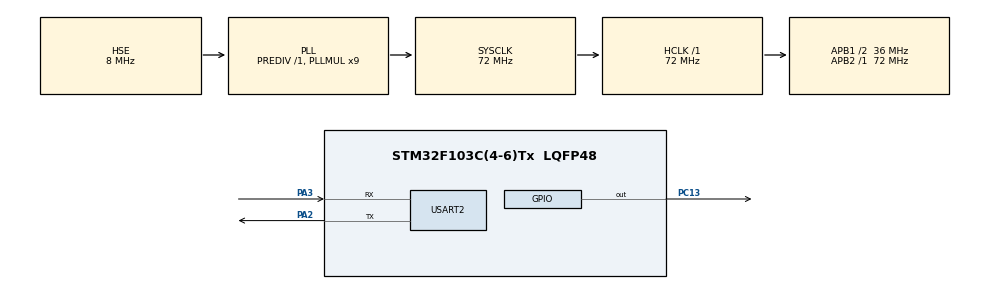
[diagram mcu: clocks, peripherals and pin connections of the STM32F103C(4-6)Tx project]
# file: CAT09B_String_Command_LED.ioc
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Mcu.Family=STM32F1
Mcu.Name=STM32F103C(4-6)Tx
Mcu.Package=LQFP48
NVIC.PriorityGroup=NVIC_PRIORITYGROUP_4
PA13.Mode=Serial_Wire
PA13.Signal=SYS_JTMS-SWDIO
PA14.Mode=Serial_Wire
PA14.Signal=SYS_JTCK-SWCLK
PA2.Mode=Asynchronous
PA2.Signal=USART2_TX
PA3.Mode=Asynchronous
PA3.Signal=USART2_RX
PC13-TAMPER-RTC.Signal=GPIO_Output
PD0-OSC_IN.Mode=HSE-External-Oscillator
PD0-OSC_IN.Signal=RCC_OSC_IN
PD1-OSC_OUT.Mode=HSE-External-Oscillator
PD1-OSC_OUT.Signal=RCC_OSC_OUT
ProjectManager.HeapSize=0x200
ProjectManager.StackSize=0x400
ProjectManager.TargetToolchain=STM32CubeIDE
RCC.AHBFreq_Value=72000000
RCC.APB1CLKDivider=RCC_HCLK_DIV2
RCC.APB1Freq_Value=36000000
RCC.APB1TimFreq_Value=72000000
RCC.APB2Freq_Value=72000000
RCC.APB2TimFreq_Value=72000000
RCC.HCLKFreq_Value=72000000
RCC.PLLMUL=RCC_PLL_MUL9
RCC.PLLSourceVirtual=RCC_PLLSOURCE_HSE
RCC.SYSCLKFreq_VALUE=72000000
RCC.SYSCLKSource=RCC_SYSCLKSOURCE_PLLCLK
RCC.USBFreq_Value=72000000
USART2.VirtualMode=VM_ASYNC
board=custom

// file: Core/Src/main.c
/* USER CODE BEGIN Header */
/**
  ******************************************************************************
  * @file           : main.c
  * @brief          : CAT 9 - Task 9B : String-based application logic over UART
  *                    Commands LED ON / LED OFF / LED TOGGLE (+ STATUS, CRLF TEST, HELP) control PC13.
  ******************************************************************************
  * @attention
  *
  * Copyright (c) 2026 STMicroelectronics.
  * All rights reserved.
  *
  * This software is licensed under terms that can be found in the LICENSE file
  * in the root directory of this software component.
  * If no LICENSE file comes with this software, it is provided AS-IS.
  *
  ******************************************************************************
  */
/* USER CODE END Header */
#include "main.h"

/* USER CODE BEGIN Includes */
#include <string.h>
#include <ctype.h>
/* USER CODE END Includes */

/* USER CODE BEGIN PD */
#define PC_UART          (&huart2)       /* USART2 PA2/PA3, 115200-8-N-1 */
#define CMD_MAX_LEN      32U

#define LED_PORT         GPIOC           /* PC13, active-low */
#define LED_PIN          GPIO_PIN_13
#define LED_ON_LEVEL     GPIO_PIN_RESET
#define LED_OFF_LEVEL    GPIO_PIN_SET
/* USER CODE END PD */

UART_HandleTypeDef huart2;

/* USER CODE BEGIN PV */
static char    cmd_buf[CMD_MAX_LEN + 1];
static uint8_t cmd_len = 0;
static uint8_t cmd_too_long = 0;   /* set when more than CMD_MAX_LEN characters arrive */
static uint8_t led_on  = 0;
/* USER CODE END PV */

void SystemClock_Config(void);
static void MX_GPIO_Init(void);
static void MX_USART2_UART_Init(void);

/* USER CODE BEGIN 0 */
static void uart_puts(const char *s)
{
  HAL_UART_Transmit(PC_UART, (uint8_t *)s, (uint16_t)strlen(s), HAL_MAX_DELAY);
}

static void uart_putc(char c)
{
  HAL_UART_Transmit(PC_UART, (uint8_t *)&c, 1, HAL_MAX_DELAY);
}

static void led_apply(void)
{
  HAL_GPIO_WritePin(LED_PORT, LED_PIN, led_on ? LED_ON_LEVEL : LED_OFF_LEVEL);
}

/* Upper-case the command and remove leading/trailing spaces, so
 * "led on", "LED ON " and " Led On" are all accepted. */
static char *normalise(char *s)
{
  char *end;
  while (*s == ' ') s++;
  for (char *p = s; *p; p++) *p = (char)toupper((unsigned char)*p);
  end = s + strlen(s);
  while (end > s && end[-1] == ' ') *--end = '\0';
  return s;
}

/* Demonstrates the effect of CR and LF on the terminal (lab sheet table) */
static void crlf_demo(void)
{
  uart_puts("HELLO\r\n");               /* new line, start of line         */
  uart_puts("HELLO\r");                 /* back to start: next text overwrites */
  uart_puts("HELLO\n");                 /* down one line, same column       */
  uart_puts("\r\nHELLO\r\nWORLD\r\n");  /* two separate lines               */
}

static void handle_command(char *raw)
{
  char *cmd = normalise(raw);

  if (strcmp(cmd, "LED ON") == 0)          { led_on = 1;       led_apply(); uart_puts("OK: LED is ON\r\n"); }
  else if (strcmp(cmd, "LED OFF") == 0)    { led_on = 0;       led_apply(); uart_puts("OK: LED is OFF\r\n"); }
  else if (strcmp(cmd, "LED TOGGLE") == 0) { led_on = !led_on; led_apply(); uart_puts(led_on ? "OK: LED toggled -> ON\r\n" : "OK: LED toggled -> OFF\r\n"); }
  else if (strcmp(cmd, "STATUS") == 0)     { uart_puts(led_on ? "LED is ON\r\n" : "LED is OFF\r\n"); }
  else if (strcmp(cmd, "CRLF TEST") == 0)  { crlf_demo(); }
  else if (strcmp(cmd, "HELP") == 0)       { uart_puts("Commands: LED ON | LED OFF | LED TOGGLE | STATUS | CRLF TEST | HELP\r\n"); }
  else                                     { uart_puts("ERR: unknown command '"); uart_puts(cmd); uart_puts("' (type HELP)\r\n"); }
}
/* USER CODE END 0 */

int main(void)
{

  /* MCU Configuration--------------------------------------------------------*/

  /* Reset of all peripherals, Initializes the Flash interface and the Systick. */
  HAL_Init();

  /* Configure the system clock */
  SystemClock_Config();

  /* Initialize all configured peripherals */
  MX_GPIO_Init();
  MX_USART2_UART_Init();
  /* USER CODE BEGIN 2 */
  led_on = 0;
  led_apply();
  uart_puts("\r\nCAT9B - UART command interface. Type HELP and press Enter.\r\n> ");
  /* USER CODE END 2 */

  /* Infinite loop */
  while (1)
  {

    /* USER CODE BEGIN 3 */
    uint8_t ch;

    if (HAL_UART_Receive(PC_UART, &ch, 1, HAL_MAX_DELAY) == HAL_OK)
    {
      if (ch == '\r' || ch == '\n')              /* end of command */
      {
        if (cmd_too_long)
        {
          uart_puts("\r\nERR: command too long (max 32 characters), ignored\r\n> ");
          cmd_too_long = 0;                    /* never execute a truncated command */
          cmd_len = 0;
        }
        else if (cmd_len > 0)
        {
          cmd_buf[cmd_len] = '\0';
          uart_puts("\r\n");
          handle_command(cmd_buf);
          cmd_len = 0;
          uart_puts("> ");
        }
      }
      else if (ch == '\b' || ch == 0x7F)         /* backspace / delete */
      {
        if (cmd_len > 0)
        {
          cmd_len--;
          uart_puts("\b \b");
        }
      }
      else if (cmd_len < CMD_MAX_LEN)            /* store and echo */
      {
        cmd_buf[cmd_len++] = (char)ch;
        uart_putc((char)ch);
      }
      else
      {
        cmd_too_long = 1;                      /* keep reading until Enter, then reject */
      }
    }
  }
  /* USER CODE END 3 */
}

void SystemClock_Config(void)
{
  RCC_OscInitTypeDef RCC_OscInitStruct = {0};
  RCC_ClkInitTypeDef RCC_ClkInitStruct = {0};

  /** Initializes the RCC Oscillators according to the specified parameters
  * in the RCC_OscInitTypeDef structure.
  */
  RCC_OscInitStruct.OscillatorType = RCC_OSCILLATORTYPE_HSE;
  RCC_OscInitStruct.HSEState = RCC_HSE_ON;
  RCC_OscInitStruct.HSEPredivValue = RCC_HSE_PREDIV_DIV1;
  RCC_OscInitStruct.HSIState = RCC_HSI_ON;
  RCC_OscInitStruct.PLL.PLLState = RCC_PLL_ON;
  RCC_OscInitStruct.PLL.PLLSource = RCC_PLLSOURCE_HSE;
  RCC_OscInitStruct.PLL.PLLMUL = RCC_PLL_MUL9;
  if (HAL_RCC_OscConfig(&RCC_OscInitStruct) != HAL_OK)
  {
    Error_Handler();
  }

  /** Initializes the CPU, AHB and APB buses clocks
  */
  RCC_ClkInitStruct.ClockType = RCC_CLOCKTYPE_HCLK|RCC_CLOCKTYPE_SYSCLK
                              |RCC_CLOCKTYPE_PCLK1|RCC_CLOCKTYPE_PCLK2;
  RCC_ClkInitStruct.SYSCLKSource = RCC_SYSCLKSOURCE_PLLCLK;
  RCC_ClkInitStruct.AHBCLKDivider = RCC_SYSCLK_DIV1;
  RCC_ClkInitStruct.APB1CLKDivider = RCC_HCLK_DIV2;
  RCC_ClkInitStruct.APB2CLKDivider = RCC_HCLK_DIV1;

  if (HAL_RCC_ClockConfig(&RCC_ClkInitStruct, FLASH_LATENCY_2) != HAL_OK)
  {
    Error_Handler();
  }
}

static void MX_USART2_UART_Init(void)
{

  huart2.Instance = USART2;
  huart2.Init.BaudRate = 115200;
  huart2.Init.WordLength = UART_WORDLENGTH_8B;
  huart2.Init.StopBits = UART_STOPBITS_1;
  huart2.Init.Parity = UART_PARITY_NONE;
  huart2.Init.Mode = UART_MODE_TX_RX;
  huart2.Init.HwFlowCtl = UART_HWCONTROL_NONE;
  huart2.Init.OverSampling = UART_OVERSAMPLING_16;
  if (HAL_UART_Init(&huart2) != HAL_OK)
  {
    Error_Handler();
  }

}

static void MX_GPIO_Init(void)
{
  GPIO_InitTypeDef GPIO_InitStruct = {0};

  /* GPIO Ports Clock Enable */
  __HAL_RCC_GPIOC_CLK_ENABLE();
  __HAL_RCC_GPIOD_CLK_ENABLE();
  __HAL_RCC_GPIOA_CLK_ENABLE();

  /*Configure GPIO pin Output Level */
  HAL_GPIO_WritePin(GPIOC, GPIO_PIN_13, GPIO_PIN_RESET);

  /*Configure GPIO pin : PC13 */
  GPIO_InitStruct.Pin = GPIO_PIN_13;
  GPIO_InitStruct.Mode = GPIO_MODE_OUTPUT_PP;
  GPIO_InitStruct.Pull = GPIO_NOPULL;
  GPIO_InitStruct.Speed = GPIO_SPEED_FREQ_LOW;
  HAL_GPIO_Init(GPIOC, &GPIO_InitStruct);

}

void Error_Handler(void)
{
  __disable_irq();
  while (1)
  {
  }
}
